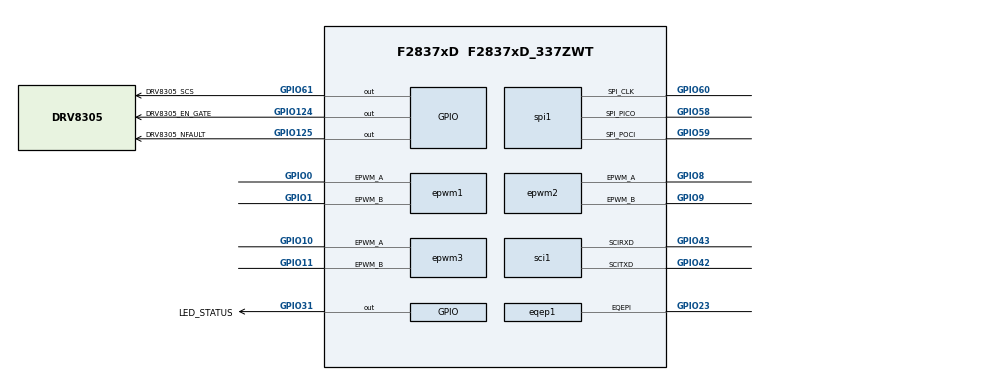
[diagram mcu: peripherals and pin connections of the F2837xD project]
/**
 * @cliArgs --device "F2837xD" --part "F2837xD_337ZWT" --package "F2837xD_337ZWT" --context "CPU1" --product "C2000WARE@26.00.00.00"
 * @versions {"tool":"1.27.1+4634"}
 */

/**
 * Import the modules used in this configuration.
 */
const adc   = scripting.addModule("/driverlib/adc.js", {}, false);
const adc1  = adc.addInstance();
const adc2  = adc.addInstance();
const adc3  = adc.addInstance();
const led   = scripting.addModule("/driverlib/board_components/led", {}, false);
const led1  = led.addInstance();
const epwm  = scripting.addModule("/driverlib/epwm.js", {}, false);
const epwm1 = epwm.addInstance();
const epwm2 = epwm.addInstance();
const epwm3 = epwm.addInstance();
const eqep  = scripting.addModule("/driverlib/eqep.js", {}, false);
const eqep1 = eqep.addInstance();
const gpio  = scripting.addModule("/driverlib/gpio.js", {}, false);
const gpio2 = gpio.addInstance();
const gpio3 = gpio.addInstance();
const gpio4 = gpio.addInstance();
const sci   = scripting.addModule("/driverlib/sci.js", {}, false);
const sci1  = sci.addInstance();
const spi   = scripting.addModule("/driverlib/spi.js", {}, false);
const spi1  = spi.addInstance();

/**
 * Write custom configuration values to the imported modules.
 */
adc1.adcClockPrescaler        = "ADC_CLK_DIV_4_0";
adc1.enabledInts              = ["ADC_INT_NUMBER1"];
adc1.interruptPulseMode       = "ADC_PULSE_END_OF_CONV";
adc1.registerInterrupts       = ["1"];
adc1.soc0Trigger              = "ADC_TRIGGER_EPWM1_SOCA";
adc1.soc0SampleWindow         = 15;
adc1.soc2Trigger              = "ADC_TRIGGER_EPWM1_SOCA";
adc1.soc2SampleWindow         = 15;
adc1.soc3Trigger              = "ADC_TRIGGER_EPWM1_SOCA";
adc1.soc3SampleWindow         = 15;
adc1.enableInterrupt1         = true;
adc1.interrupt1SOCSource      = "ADC_SOC_NUMBER3";
adc1.$name                    = "myADCA";
adc1.enabledSOCs              = ["ADC_SOC_NUMBER2","ADC_SOC_NUMBER3"];
adc1.soc2Channel              = "ADC_CH_ADCIN2";
adc1.soc3Channel              = "ADC_CH_ADCIN3";
adc1.adcInt1.enableInterrupt  = true;
adc1.adcInt1.interruptHandler = "adcA1_isr";

adc2.adcBase           = "ADCB_BASE";
adc2.adcClockPrescaler = "ADC_CLK_DIV_4_0";
adc2.enabledSOCs       = ["ADC_SOC_NUMBER1"];
adc2.soc1Trigger       = "ADC_TRIGGER_EPWM1_SOCA";
adc2.soc1SampleWindow  = 15;
adc2.$name             = "myADCB";
adc2.soc1Channel       = "ADC_CH_ADCIN2";

adc3.$name             = "myADCC";
adc3.adcBase           = "ADCC_BASE";
adc3.enabledSOCs       = ["ADC_SOC_NUMBER0"];
adc3.soc0Trigger       = "ADC_TRIGGER_EPWM1_SOCA";
adc3.soc0Channel       = "ADC_CH_ADCIN2";
adc3.soc0SampleWindow  = 15;
adc3.adcClockPrescaler = "ADC_CLK_DIV_4_0";

led1.$name                = "LED_STATUS";
led1.gpio.gpioPin.$assign = "GPIO31";

epwm1.epwmEventTrigger_EPWM_SOC_A_triggerEnable                  = true;
epwm1.$name                                                      = "PWM_W";
epwm1.epwmTimebase_counterMode                                   = "EPWM_COUNTER_MODE_UP_DOWN";
epwm1.epwmTimebase_period                                        = 5000;
epwm1.epwmTimebase_syncOutPulseMode                              = "EPWM_SYNC_OUT_PULSE_ON_COUNTER_ZERO";
epwm1.epwmCounterCompare_cmpA                                    = 2500;
epwm1.epwmActionQualifier_EPWM_AQ_OUTPUT_A_ON_TIMEBASE_UP_CMPA   = "EPWM_AQ_OUTPUT_HIGH";
epwm1.epwmActionQualifier_EPWM_AQ_OUTPUT_A_ON_TIMEBASE_DOWN_CMPA = "EPWM_AQ_OUTPUT_LOW";
epwm1.epwmDeadband_enableRED                                     = true;
epwm1.epwmDeadband_enableFED                                     = true;
epwm1.epwmDeadband_delayRED                                      = 50;
epwm1.epwmDeadband_delayFED                                      = 50;
epwm1.epwmDeadband_polarityFED                                   = "EPWM_DB_POLARITY_ACTIVE_LOW";
epwm1.epwmEventTrigger_EPWM_SOC_A_triggerSource                  = "EPWM_SOC_TBCTR_ZERO";
epwm1.epwmEventTrigger_EPWM_SOC_A_triggerEventPrescalar          = "1";
epwm1.epwm.$assign                                               = "EPWM1";
epwm1.epwm.epwm_aPin.$assign                                     = "GPIO0";
epwm1.epwm.epwm_bPin.$assign                                     = "GPIO1";

epwm2.$name                                                      = "PWM_V";
epwm2.epwmTimebase_counterMode                                   = "EPWM_COUNTER_MODE_UP_DOWN";
epwm2.epwmTimebase_period                                        = 5000;
epwm2.epwmTimebase_syncOutPulseMode                              = "EPWM_SYNC_OUT_PULSE_ON_EPWMxSYNCIN";
epwm2.epwmTimebase_phaseEnable                                   = true;
epwm2.epwmCounterCompare_cmpA                                    = 2500;
epwm2.epwmActionQualifier_EPWM_AQ_OUTPUT_A_ON_TIMEBASE_UP_CMPA   = "EPWM_AQ_OUTPUT_HIGH";
epwm2.epwmActionQualifier_EPWM_AQ_OUTPUT_A_ON_TIMEBASE_DOWN_CMPA = "EPWM_AQ_OUTPUT_LOW";
epwm2.epwmDeadband_enableRED                                     = true;
epwm2.epwmDeadband_enableFED                                     = true;
epwm2.epwmDeadband_delayRED                                      = 50;
epwm2.epwmDeadband_delayFED                                      = 50;
epwm2.epwmDeadband_polarityFED                                   = "EPWM_DB_POLARITY_ACTIVE_LOW";
epwm2.epwmTimebase_counterModeAfterSync                          = "EPWM_COUNT_MODE_UP_AFTER_SYNC";
epwm2.epwm.$assign                                               = "EPWM5";
epwm2.epwm.epwm_aPin.$assign                                     = "GPIO8";
epwm2.epwm.epwm_bPin.$assign                                     = "GPIO9";

epwm3.$name                                                      = "PWM_U";
epwm3.epwmTimebase_counterMode                                   = "EPWM_COUNTER_MODE_UP_DOWN";
epwm3.epwmTimebase_period                                        = 5000;
epwm3.epwmTimebase_syncOutPulseMode                              = "EPWM_SYNC_OUT_PULSE_ON_EPWMxSYNCIN";
epwm3.epwmTimebase_phaseEnable                                   = true;
epwm3.epwmCounterCompare_cmpA                                    = 2500;
epwm3.epwmActionQualifier_EPWM_AQ_OUTPUT_A_ON_TIMEBASE_UP_CMPA   = "EPWM_AQ_OUTPUT_HIGH";
epwm3.epwmActionQualifier_EPWM_AQ_OUTPUT_A_ON_TIMEBASE_DOWN_CMPA = "EPWM_AQ_OUTPUT_LOW";
epwm3.epwmDeadband_enableRED                                     = true;
epwm3.epwmDeadband_enableFED                                     = true;
epwm3.epwmDeadband_delayRED                                      = 50;
epwm3.epwmDeadband_delayFED                                      = 50;
epwm3.epwmDeadband_polarityFED                                   = "EPWM_DB_POLARITY_ACTIVE_LOW";
epwm3.epwmTimebase_counterModeAfterSync                          = "EPWM_COUNT_MODE_UP_AFTER_SYNC";
epwm3.epwm.$assign                                               = "EPWM6";
epwm3.epwm.epwm_aPin.$assign                                     = "GPIO10";
epwm3.epwm.epwm_bPin.$assign                                     = "GPIO11";

eqep1.$name                 = "QEP_SENSOR";
eqep1.useCase               = "NO STROBE";
eqep1.positionCounterMode   = "EQEP_POSITION_RESET_MAX_POS";
eqep1.positionCounterMax    = 15999;
eqep1.enableModule          = true;
eqep1.emulationMode         = "EQEP_EMULATIONMODE_RUNFREE";
eqep1.eqep.eqepiPin.$assign = "GPIO23";

gpio2.$name             = "DRV8305_EN_GATE";
gpio2.direction         = "GPIO_DIR_MODE_OUT";
gpio2.writeInitialValue = true;
gpio2.gpioPin.$assign   = "GPIO124";

gpio3.$name           = "DRV8305_NFAULT";
gpio3.padConfig       = "PULLUP";
gpio3.gpioPin.$assign = "GPIO125";

gpio4.$name             = "DRV8305_SCS";
gpio4.direction         = "GPIO_DIR_MODE_OUT";
gpio4.writeInitialValue = true;
gpio4.initialValue      = 1;
gpio4.gpioPin.$assign   = "GPIO61";

sci1.$name                      = "UART_DEBUG";
sci1.useCase                    = "CUSTOM";
sci1.selectRegisteredInterrupts = ["registerRxInt"];
sci1.enabledFIFOInterrupts      = ["SCI_INT_RXFF"];
sci1.rxFifo                     = "SCI_FIFO_RX4";
sci1.useInterfacePins           = ["SCIRXD@","SCITXD@"];
sci1.sciRXInt.interruptHandler  = "sciA_rx_isr";
sci1.sciRXInt.enableInterrupt   = true;
sci1.sci.scirxdPin.$assign      = "GPIO43";
sci1.sci.scitxdPin.$assign      = "GPIO42";
sci1.rxQual.$name               = "myGPIOQUAL0";
sci1.txQual.$name               = "myGPIOQUAL1";

spi1.$name                   = "DRV8305_SPI";
spi1.mode                    = "SPI_MODE_CONTROLLER";
spi1.useCase                 = "CUSTOM";
spi1.useInterfacePins        = ["SPICLK@","SPISIMO@","SPISOMI@"];
spi1.spi.spi_picoPin.$assign = "GPIO58";
spi1.spi.spi_pociPin.$assign = "GPIO59";
spi1.spi.spi_clkPin.$assign  = "GPIO60";
spi1.clkQual.$name           = "myGPIOQUAL2";
spi1.picoQual.$name          = "myGPIOQUAL3";
spi1.pociQual.$name          = "myGPIOQUAL4";

/**
 * Pinmux solution for unlocked pins/peripherals. This ensures that minor changes to the automatic solver in a future
 * version of the tool will not impact the pinmux you originally saw.  These lines can be completely deleted in order to
 * re-solve from scratch.
 */
eqep1.eqep.$suggestSolution          = "EQEP1";
eqep1.eqep.eqepaPin.$suggestSolution = "GPIO20";
eqep1.eqep.eqepbPin.$suggestSolution = "GPIO21";
sci1.sci.$suggestSolution            = "SCIA";
spi1.spi.$suggestSolution            = "SPIA";
